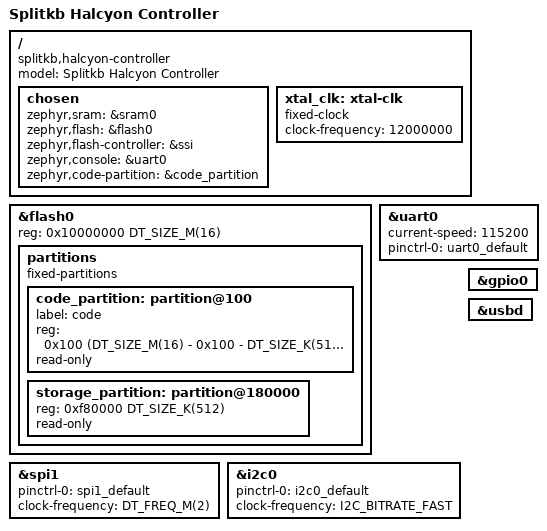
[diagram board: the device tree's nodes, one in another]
/*
 * Copyright (c) 2021 Yonatan Schachter
 *
 * SPDX-License-Identifier: Apache-2.0
 */

/dts-v1/;

#include <rpi_pico/rp2040.dtsi>
#include "splitkb_halcyon_controller-pinctrl.dtsi"
#include "splitkb_halcyon_connector.dtsi"
#include <freq.h>

/ {
	model = "Splitkb Halcyon Controller";
	compatible = "splitkb,halcyon-controller", "raspberrypi,rp2040";

	chosen {
		zephyr,sram = &sram0;
		zephyr,flash = &flash0;
		zephyr,flash-controller = &ssi;
		zephyr,console = &uart0;
		zephyr,code-partition = &code_partition;
	};

	xtal_clk: xtal-clk {
		compatible = "fixed-clock";
		clock-frequency = <12000000>;
		#clock-cells = <0>;
	};
};

&flash0 {
	/* 8MB of flash minus the 0x100 used for
	 * the second stage bootloader
	 */
	reg = <0x10000000 DT_SIZE_M(16)>;

	partitions {
		compatible = "fixed-partitions";
		#address-cells = <1>;
		#size-cells = <1>;

		/*
		 * Start at the beginning of usable flash, 8MB minus the
		 * second stage space and the 16 KiB reserved for settings
		 */
		code_partition: partition@100 {
			label = "code";
			reg = <0x100 (DT_SIZE_M(16) - 0x100 - DT_SIZE_K(512))>;
			read-only;
		};

		storage_partition: partition@180000 {
			reg = <0xf80000 DT_SIZE_K(512)>;
			read-only;
		};
	};
};

&uart0 {
	current-speed = <115200>;
	status = "okay";
	pinctrl-0 = <&uart0_default>;
	pinctrl-names = "default";
};

&spi1 {
	status = "okay";
	pinctrl-0 = <&spi1_default>;
	pinctrl-names = "default";
	clock-frequency = <DT_FREQ_M(2)>;
};

&i2c0 {
	status = "okay";
	pinctrl-0 = <&i2c0_default>;
	pinctrl-names = "default";
	clock-frequency = <I2C_BITRATE_FAST>;
};

&gpio0 {
	status = "okay";
};

zephyr_udc0: &usbd {
	status = "okay";
};
